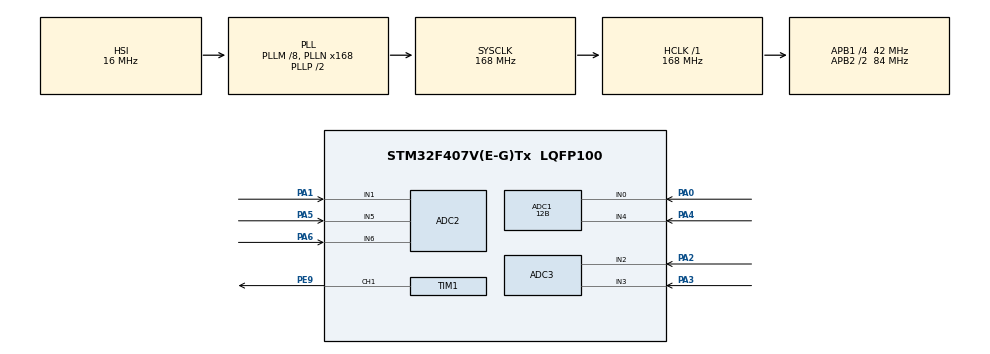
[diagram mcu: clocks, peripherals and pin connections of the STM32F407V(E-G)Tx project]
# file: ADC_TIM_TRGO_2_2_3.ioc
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ADC1.Channel-39\#ChannelRegularConversion=ADC_CHANNEL_0
ADC1.Channel-40\#ChannelInjectedConversion=ADC_CHANNEL_0
ADC1.Channel-41\#ChannelInjectedConversion=ADC_CHANNEL_4
ADC1.ClockPrescaler=ADC_CLOCK_SYNC_PCLK_DIV4
ADC1.ContinuousConvMode=DISABLE
ADC1.DMAContinuousRequests=DISABLE
ADC1.DataAlign=ADC_DATAALIGN_RIGHT
ADC1.DiscontinuousConvMode=DISABLE
ADC1.EOCSelection=ADC_EOC_SINGLE_CONV
ADC1.EnableAnalogWatchDog=false
ADC1.ExternalTrigConv=ADC_SOFTWARE_START
ADC1.ExternalTrigConvEdge=ADC_EXTERNALTRIGCONVEDGE_NONE
ADC1.ExternalTrigInjecConv=ADC_EXTERNALTRIGINJECCONV_T1_TRGO
ADC1.ExternalTrigInjecConvEdge=ADC_EXTERNALTRIGINJECCONVEDGE_RISING
ADC1.InjNumberOfConversion=2
ADC1.InjectedConvMode=None
ADC1.InjectedOffset-40\#ChannelInjectedConversion=0
ADC1.InjectedOffset-41\#ChannelInjectedConversion=0
ADC1.NbrOfConversion=1
ADC1.NbrOfConversionFlag=1
ADC1.Rank-39\#ChannelRegularConversion=1
ADC1.Rank-40\#ChannelInjectedConversion=1
ADC1.Rank-41\#ChannelInjectedConversion=2
ADC1.Resolution=ADC_RESOLUTION_12B
ADC1.SamplingTime-39\#ChannelRegularConversion=ADC_SAMPLETIME_3CYCLES
ADC1.SamplingTime-40\#ChannelInjectedConversion=ADC_SAMPLETIME_3CYCLES
ADC1.SamplingTime-41\#ChannelInjectedConversion=ADC_SAMPLETIME_3CYCLES
ADC1.ScanConvMode=ENABLE
ADC1.master=1
ADC2.Channel-0\#ChannelRegularConversion=ADC_CHANNEL_1
ADC2.Channel-1\#ChannelInjectedConversion=ADC_CHANNEL_1
ADC2.Channel-2\#ChannelInjectedConversion=ADC_CHANNEL_5
ADC2.Channel-3\#ChannelInjectedConversion=ADC_CHANNEL_6
ADC2.ContinuousConvMode=DISABLE
ADC2.ExternalTrigInjecConv=ADC_EXTERNALTRIGINJECCONV_T1_TRGO
ADC2.InjNumberOfConversion=3
ADC2.InjectedOffset-1\#ChannelInjectedConversion=0
ADC2.InjectedOffset-2\#ChannelInjectedConversion=0
ADC2.InjectedOffset-3\#ChannelInjectedConversion=0
ADC2.NbrOfConversionFlag=1
ADC2.Rank-0\#ChannelRegularConversion=1
ADC2.Rank-1\#ChannelInjectedConversion=1
ADC2.Rank-2\#ChannelInjectedConversion=2
ADC2.Rank-3\#ChannelInjectedConversion=3
ADC2.SamplingTime-0\#ChannelRegularConversion=ADC_SAMPLETIME_3CYCLES
ADC2.SamplingTime-1\#ChannelInjectedConversion=ADC_SAMPLETIME_3CYCLES
ADC2.SamplingTime-2\#ChannelInjectedConversion=ADC_SAMPLETIME_3CYCLES
ADC2.SamplingTime-3\#ChannelInjectedConversion=ADC_SAMPLETIME_3CYCLES
ADC2.ScanConvMode=ENABLE
ADC3.Channel-4\#ChannelRegularConversion=ADC_CHANNEL_2
ADC3.Channel-5\#ChannelInjectedConversion=ADC_CHANNEL_2
ADC3.Channel-6\#ChannelInjectedConversion=ADC_CHANNEL_3
ADC3.ContinuousConvMode=DISABLE
ADC3.ExternalTrigInjecConv=ADC_EXTERNALTRIGINJECCONV_T1_TRGO
ADC3.InjNumberOfConversion=2
ADC3.InjectedOffset-5\#ChannelInjectedConversion=0
ADC3.InjectedOffset-6\#ChannelInjectedConversion=0
ADC3.NbrOfConversionFlag=1
ADC3.Rank-4\#ChannelRegularConversion=1
ADC3.Rank-5\#ChannelInjectedConversion=1
ADC3.Rank-6\#ChannelInjectedConversion=2
ADC3.SamplingTime-4\#ChannelRegularConversion=ADC_SAMPLETIME_3CYCLES
ADC3.SamplingTime-5\#ChannelInjectedConversion=ADC_SAMPLETIME_3CYCLES
ADC3.SamplingTime-6\#ChannelInjectedConversion=ADC_SAMPLETIME_3CYCLES
ADC3.ScanConvMode=ENABLE
Mcu.Family=STM32F4
Mcu.Name=STM32F407V(E-G)Tx
Mcu.Package=LQFP100
NVIC.ADC_IRQn=true\:0\:0\:false\:false\:true
NVIC.PriorityGroup=NVIC_PRIORITYGROUP_4
PA0-WKUP.Signal=ADCx_IN0
PA1.Signal=ADCx_IN1
PA2.Signal=ADCx_IN2
PA3.Signal=ADCx_IN3
PA4.Signal=ADCx_IN4
PA5.Signal=ADCx_IN5
PA6.Signal=ADCx_IN6
PE9.Signal=S_TIM1_CH1
ProjectManager.HeapSize=0x200
ProjectManager.StackSize=0x400
ProjectManager.TargetToolchain=TrueSTUDIO
RCC.48MHZClocksFreq_Value=84000000
RCC.AHBFreq_Value=168000000
RCC.APB1CLKDivider=RCC_HCLK_DIV4
RCC.APB1Freq_Value=42000000
RCC.APB1TimFreq_Value=84000000
RCC.APB2CLKDivider=RCC_HCLK_DIV2
RCC.APB2Freq_Value=84000000
RCC.APB2TimFreq_Value=168000000
RCC.CortexFreq_Value=168000000
RCC.HCLKFreq_Value=168000000
RCC.HSE_VALUE=25000000
RCC.HSI_VALUE=16000000
RCC.LSE_VALUE=32768
RCC.PLLM=8
RCC.PLLN=168
RCC.SYSCLKFreq_VALUE=168000000
RCC.SYSCLKSource=RCC_SYSCLKSOURCE_PLLCLK
RCC.VCOOutputFreq_Value=336000000
SH.ADCx_IN0.0=ADC1_IN0,IN0
SH.ADCx_IN1.0=ADC2_IN1,IN1
SH.ADCx_IN2.0=ADC3_IN2,IN2
SH.ADCx_IN3.0=ADC3_IN3,IN3
SH.ADCx_IN4.0=ADC1_IN4,IN4
SH.ADCx_IN5.0=ADC2_IN5,IN5
SH.ADCx_IN6.0=ADC2_IN6,IN6
SH.S_TIM1_CH1.0=TIM1_CH1,PWM Generation1 CH1
TIM1.Channel-PWM\ Generation1\ CH1=TIM_CHANNEL_1
TIM1.Period=4096
TIM1.Prescaler=1
TIM1.Pulse-PWM\ Generation1\ CH1=0
TIM1.TIM_MasterOutputTrigger=TIM_TRGO_UPDATE
TIM1.TIM_MasterSlaveMode=TIM_MASTERSLAVEMODE_ENABLE
board=ADC_TIM_TRGO_2_2_3

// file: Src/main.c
/**
  ******************************************************************************
  * File Name          : main.c
  * Description        : Main program body
  ******************************************************************************
  ** This notice applies to any and all portions of this file
  * that are not between comment pairs USER CODE BEGIN and
  * USER CODE END. Other portions of this file, whether
  * inserted by the user or by software development tools
  * are owned by their respective copyright owners.
  *
  * COPYRIGHT(c) 2021 STMicroelectronics
  *
  * Redistribution and use in source and binary forms, with or without modification,
  * are permitted provided that the following conditions are met:
  *   1. Redistributions of source code must retain the above copyright notice,
  *      this list of conditions and the following disclaimer.
  *   2. Redistributions in binary form must reproduce the above copyright notice,
  *      this list of conditions and the following disclaimer in the documentation
  *      and/or other materials provided with the distribution.
  *   3. Neither the name of STMicroelectronics nor the names of its contributors
  *      may be used to endorse or promote products derived from this software
  *      without specific prior written permission.
  *
  * THIS SOFTWARE IS PROVIDED BY THE COPYRIGHT HOLDERS AND CONTRIBUTORS "AS IS"
  * AND ANY EXPRESS OR IMPLIED WARRANTIES, INCLUDING, BUT NOT LIMITED TO, THE
  * IMPLIED WARRANTIES OF MERCHANTABILITY AND FITNESS FOR A PARTICULAR PURPOSE ARE
  * DISCLAIMED. IN NO EVENT SHALL THE COPYRIGHT HOLDER OR CONTRIBUTORS BE LIABLE
  * FOR ANY DIRECT, INDIRECT, INCIDENTAL, SPECIAL, EXEMPLARY, OR CONSEQUENTIAL
  * DAMAGES (INCLUDING, BUT NOT LIMITED TO, PROCUREMENT OF SUBSTITUTE GOODS OR
  * SERVICES; LOSS OF USE, DATA, OR PROFITS; OR BUSINESS INTERRUPTION) HOWEVER
  * CAUSED AND ON ANY THEORY OF LIABILITY, WHETHER IN CONTRACT, STRICT LIABILITY,
  * OR TORT (INCLUDING NEGLIGENCE OR OTHERWISE) ARISING IN ANY WAY OUT OF THE USE
  * OF THIS SOFTWARE, EVEN IF ADVISED OF THE POSSIBILITY OF SUCH DAMAGE.
  *
  ******************************************************************************
  */
#include "main.h"
#include "stm32f4xx_hal.h"

ADC_HandleTypeDef hadc1;
ADC_HandleTypeDef hadc2;
ADC_HandleTypeDef hadc3;

TIM_HandleTypeDef htim1;

/* USER CODE BEGIN PV */
/* Private variables ---------------------------------------------------------*/

/* USER CODE END PV */

void SystemClock_Config(void);
static void MX_GPIO_Init(void);
static void MX_ADC3_Init(void);
static void MX_ADC2_Init(void);
static void MX_ADC1_Init(void);
static void MX_TIM1_Init(void);

void HAL_TIM_MspPostInit(TIM_HandleTypeDef *htim);

/* USER CODE BEGIN PFP */
/* Private function prototypes -----------------------------------------------*/

/* USER CODE END PFP */

int main(void)
{

  /* MCU Configuration----------------------------------------------------------*/

  /* Reset of all peripherals, Initializes the Flash interface and the Systick. */
  HAL_Init();

  /* Configure the system clock */
  SystemClock_Config();

  /* Initialize all configured peripherals */
  MX_GPIO_Init();
  MX_ADC3_Init();
  MX_ADC2_Init();
  MX_ADC1_Init();
  MX_TIM1_Init();

  /* USER CODE END 2 */
  /* USER CODE BEGIN 2 */
  /* USER CODE BEGIN 2 */
  HAL_ADCEx_InjectedStart_IT(&hadc1);
  HAL_ADCEx_InjectedStart_IT(&hadc2);
  HAL_ADCEx_InjectedStart_IT(&hadc3);
  /* USER CODE END 2 */

  /* Infinite loop */
  while (1)
  {

  }

}

__IO uint16_t value0 = 0;
__IO uint16_t value1 = 0;
__IO uint16_t value2 = 0;
__IO uint16_t value3 = 0;
__IO uint16_t value4 = 0;
__IO uint16_t value5 = 0;
__IO uint16_t value6 = 0;

void HAL_ADCEx_InjectedConvCpltCallback(ADC_HandleTypeDef* AdcHandle)
{
  /* Get the converted value of injected channel */
  if (AdcHandle == &hadc1)
  {
  	  value0 = HAL_ADCEx_InjectedGetValue(AdcHandle, ADC_INJECTED_RANK_1);
  	  value1 = HAL_ADCEx_InjectedGetValue(AdcHandle, ADC_INJECTED_RANK_2);

  }

  if (AdcHandle == &hadc2)
  {
  	  value2 = HAL_ADCEx_InjectedGetValue(AdcHandle, ADC_INJECTED_RANK_1);
  	  value3 = HAL_ADCEx_InjectedGetValue(AdcHandle, ADC_INJECTED_RANK_2);
  	  value4 = HAL_ADCEx_InjectedGetValue(AdcHandle, ADC_INJECTED_RANK_3);
  }

  if (AdcHandle == &hadc3)
  {

  	  value5 = HAL_ADCEx_InjectedGetValue(AdcHandle, ADC_INJECTED_RANK_1);
  	  value6 = HAL_ADCEx_InjectedGetValue(AdcHandle, ADC_INJECTED_RANK_2);
  }

}

/** System Clock Configuration
*/
void SystemClock_Config(void)
{

  RCC_OscInitTypeDef RCC_OscInitStruct;
  RCC_ClkInitTypeDef RCC_ClkInitStruct;

    /**Configure the main internal regulator output voltage
    */
  __HAL_RCC_PWR_CLK_ENABLE();

  __HAL_PWR_VOLTAGESCALING_CONFIG(PWR_REGULATOR_VOLTAGE_SCALE1);

    /**Initializes the CPU, AHB and APB busses clocks
    */
  RCC_OscInitStruct.OscillatorType = RCC_OSCILLATORTYPE_HSI;
  RCC_OscInitStruct.HSIState = RCC_HSI_ON;
  RCC_OscInitStruct.HSICalibrationValue = 16;
  RCC_OscInitStruct.PLL.PLLState = RCC_PLL_ON;
  RCC_OscInitStruct.PLL.PLLSource = RCC_PLLSOURCE_HSI;
  RCC_OscInitStruct.PLL.PLLM = 8;
  RCC_OscInitStruct.PLL.PLLN = 168;
  RCC_OscInitStruct.PLL.PLLP = RCC_PLLP_DIV2;
  RCC_OscInitStruct.PLL.PLLQ = 4;
  if (HAL_RCC_OscConfig(&RCC_OscInitStruct) != HAL_OK)
  {
    _Error_Handler(__FILE__, __LINE__);
  }

    /**Initializes the CPU, AHB and APB busses clocks
    */
  RCC_ClkInitStruct.ClockType = RCC_CLOCKTYPE_HCLK|RCC_CLOCKTYPE_SYSCLK
                              |RCC_CLOCKTYPE_PCLK1|RCC_CLOCKTYPE_PCLK2;
  RCC_ClkInitStruct.SYSCLKSource = RCC_SYSCLKSOURCE_PLLCLK;
  RCC_ClkInitStruct.AHBCLKDivider = RCC_SYSCLK_DIV1;
  RCC_ClkInitStruct.APB1CLKDivider = RCC_HCLK_DIV4;
  RCC_ClkInitStruct.APB2CLKDivider = RCC_HCLK_DIV2;

  if (HAL_RCC_ClockConfig(&RCC_ClkInitStruct, FLASH_LATENCY_5) != HAL_OK)
  {
    _Error_Handler(__FILE__, __LINE__);
  }

    /**Configure the Systick interrupt time
    */
  HAL_SYSTICK_Config(HAL_RCC_GetHCLKFreq()/1000);

    /**Configure the Systick
    */
  HAL_SYSTICK_CLKSourceConfig(SYSTICK_CLKSOURCE_HCLK);

  /* SysTick_IRQn interrupt configuration */
  HAL_NVIC_SetPriority(SysTick_IRQn, 0, 0);
}

/* ADC1 init function */
static void MX_ADC1_Init(void)
{

  ADC_ChannelConfTypeDef sConfig;
  ADC_InjectionConfTypeDef sConfigInjected;

    /**Configure the global features of the ADC (Clock, Resolution, Data Alignment and number of conversion)
    */
  hadc1.Instance = ADC1;
  hadc1.Init.ClockPrescaler = ADC_CLOCK_SYNC_PCLK_DIV4;
  hadc1.Init.Resolution = ADC_RESOLUTION_12B;
  hadc1.Init.ScanConvMode = ENABLE;
  hadc1.Init.ContinuousConvMode = DISABLE;
  hadc1.Init.DiscontinuousConvMode = DISABLE;
  hadc1.Init.ExternalTrigConvEdge = ADC_EXTERNALTRIGCONVEDGE_NONE;
  hadc1.Init.ExternalTrigConv = ADC_SOFTWARE_START;
  hadc1.Init.DataAlign = ADC_DATAALIGN_RIGHT;
  hadc1.Init.NbrOfConversion = 1;
  hadc1.Init.DMAContinuousRequests = DISABLE;
  hadc1.Init.EOCSelection = ADC_EOC_SINGLE_CONV;
  if (HAL_ADC_Init(&hadc1) != HAL_OK)
  {
    _Error_Handler(__FILE__, __LINE__);
  }

    /**Configure for the selected ADC regular channel its corresponding rank in the sequencer and its sample time.
    */
  sConfig.Channel = ADC_CHANNEL_0;
  sConfig.Rank = 1;
  sConfig.SamplingTime = ADC_SAMPLETIME_3CYCLES;
  if (HAL_ADC_ConfigChannel(&hadc1, &sConfig) != HAL_OK)
  {
    _Error_Handler(__FILE__, __LINE__);
  }

    /**Configures for the selected ADC injected channel its corresponding rank in the sequencer and its sample time
    */
  sConfigInjected.InjectedChannel = ADC_CHANNEL_0;
  sConfigInjected.InjectedRank = 1;
  sConfigInjected.InjectedNbrOfConversion = 2;
  sConfigInjected.InjectedSamplingTime = ADC_SAMPLETIME_3CYCLES;
  sConfigInjected.ExternalTrigInjecConvEdge = ADC_EXTERNALTRIGINJECCONVEDGE_RISING;
  sConfigInjected.ExternalTrigInjecConv = ADC_EXTERNALTRIGINJECCONV_T1_TRGO;
  sConfigInjected.AutoInjectedConv = DISABLE;
  sConfigInjected.InjectedDiscontinuousConvMode = DISABLE;
  sConfigInjected.InjectedOffset = 0;
  if (HAL_ADCEx_InjectedConfigChannel(&hadc1, &sConfigInjected) != HAL_OK)
  {
    _Error_Handler(__FILE__, __LINE__);
  }

    /**Configures for the selected ADC injected channel its corresponding rank in the sequencer and its sample time
    */
  sConfigInjected.InjectedChannel = ADC_CHANNEL_4;
  sConfigInjected.InjectedRank = 2;
  if (HAL_ADCEx_InjectedConfigChannel(&hadc1, &sConfigInjected) != HAL_OK)
  {
    _Error_Handler(__FILE__, __LINE__);
  }

}

/* ADC2 init function */
static void MX_ADC2_Init(void)
{

  ADC_ChannelConfTypeDef sConfig;
  ADC_InjectionConfTypeDef sConfigInjected;

    /**Configure the global features of the ADC (Clock, Resolution, Data Alignment and number of conversion)
    */
  hadc2.Instance = ADC2;
  hadc2.Init.ClockPrescaler = ADC_CLOCK_SYNC_PCLK_DIV4;
  hadc2.Init.Resolution = ADC_RESOLUTION_12B;
  hadc2.Init.ScanConvMode = ENABLE;
  hadc2.Init.ContinuousConvMode = DISABLE;
  hadc2.Init.DiscontinuousConvMode = DISABLE;
  hadc2.Init.ExternalTrigConvEdge = ADC_EXTERNALTRIGCONVEDGE_NONE;
  hadc2.Init.ExternalTrigConv = ADC_SOFTWARE_START;
  hadc2.Init.DataAlign = ADC_DATAALIGN_RIGHT;
  hadc2.Init.NbrOfConversion = 1;
  hadc2.Init.DMAContinuousRequests = DISABLE;
  hadc2.Init.EOCSelection = ADC_EOC_SINGLE_CONV;
  if (HAL_ADC_Init(&hadc2) != HAL_OK)
  {
    _Error_Handler(__FILE__, __LINE__);
  }

    /**Configure for the selected ADC regular channel its corresponding rank in the sequencer and its sample time.
    */
  sConfig.Channel = ADC_CHANNEL_1;
  sConfig.Rank = 1;
  sConfig.SamplingTime = ADC_SAMPLETIME_3CYCLES;
  if (HAL_ADC_ConfigChannel(&hadc2, &sConfig) != HAL_OK)
  {
    _Error_Handler(__FILE__, __LINE__);
  }

    /**Configures for the selected ADC injected channel its corresponding rank in the sequencer and its sample time
    */
  sConfigInjected.InjectedChannel = ADC_CHANNEL_1;
  sConfigInjected.InjectedRank = 1;
  sConfigInjected.InjectedNbrOfConversion = 3;
  sConfigInjected.InjectedSamplingTime = ADC_SAMPLETIME_3CYCLES;
  sConfigInjected.ExternalTrigInjecConvEdge = ADC_EXTERNALTRIGINJECCONVEDGE_RISING;
  sConfigInjected.ExternalTrigInjecConv = ADC_EXTERNALTRIGINJECCONV_T1_TRGO;
  sConfigInjected.AutoInjectedConv = DISABLE;
  sConfigInjected.InjectedDiscontinuousConvMode = DISABLE;
  sConfigInjected.InjectedOffset = 0;
  if (HAL_ADCEx_InjectedConfigChannel(&hadc2, &sConfigInjected) != HAL_OK)
  {
    _Error_Handler(__FILE__, __LINE__);
  }

    /**Configures for the selected ADC injected channel its corresponding rank in the sequencer and its sample time
    */
  sConfigInjected.InjectedChannel = ADC_CHANNEL_5;
  sConfigInjected.InjectedRank = 2;
  if (HAL_ADCEx_InjectedConfigChannel(&hadc2, &sConfigInjected) != HAL_OK)
  {
    _Error_Handler(__FILE__, __LINE__);
  }

    /**Configures for the selected ADC injected channel its corresponding rank in the sequencer and its sample time
    */
  sConfigInjected.InjectedChannel = ADC_CHANNEL_6;
  sConfigInjected.InjectedRank = 3;
  if (HAL_ADCEx_InjectedConfigChannel(&hadc2, &sConfigInjected) != HAL_OK)
  {
    _Error_Handler(__FILE__, __LINE__);
  }

}

/* ADC3 init function */
static void MX_ADC3_Init(void)
{

  ADC_ChannelConfTypeDef sConfig;
  ADC_InjectionConfTypeDef sConfigInjected;

    /**Configure the global features of the ADC (Clock, Resolution, Data Alignment and number of conversion)
    */
  hadc3.Instance = ADC3;
  hadc3.Init.ClockPrescaler = ADC_CLOCK_SYNC_PCLK_DIV4;
  hadc3.Init.Resolution = ADC_RESOLUTION_12B;
  hadc3.Init.ScanConvMode = ENABLE;
  hadc3.Init.ContinuousConvMode = DISABLE;
  hadc3.Init.DiscontinuousConvMode = DISABLE;
  hadc3.Init.ExternalTrigConvEdge = ADC_EXTERNALTRIGCONVEDGE_NONE;
  hadc3.Init.ExternalTrigConv = ADC_SOFTWARE_START;
  hadc3.Init.DataAlign = ADC_DATAALIGN_RIGHT;
  hadc3.Init.NbrOfConversion = 1;
  hadc3.Init.DMAContinuousRequests = DISABLE;
  hadc3.Init.EOCSelection = ADC_EOC_SINGLE_CONV;
  if (HAL_ADC_Init(&hadc3) != HAL_OK)
  {
    _Error_Handler(__FILE__, __LINE__);
  }

    /**Configure for the selected ADC regular channel its corresponding rank in the sequencer and its sample time.
    */
  sConfig.Channel = ADC_CHANNEL_2;
  sConfig.Rank = 1;
  sConfig.SamplingTime = ADC_SAMPLETIME_3CYCLES;
  if (HAL_ADC_ConfigChannel(&hadc3, &sConfig) != HAL_OK)
  {
    _Error_Handler(__FILE__, __LINE__);
  }

    /**Configures for the selected ADC injected channel its corresponding rank in the sequencer and its sample time
    */
  sConfigInjected.InjectedChannel = ADC_CHANNEL_2;
  sConfigInjected.InjectedRank = 1;
  sConfigInjected.InjectedNbrOfConversion = 2;
  sConfigInjected.InjectedSamplingTime = ADC_SAMPLETIME_3CYCLES;
  sConfigInjected.ExternalTrigInjecConvEdge = ADC_EXTERNALTRIGINJECCONVEDGE_RISING;
  sConfigInjected.ExternalTrigInjecConv = ADC_EXTERNALTRIGINJECCONV_T1_TRGO;
  sConfigInjected.AutoInjectedConv = DISABLE;
  sConfigInjected.InjectedDiscontinuousConvMode = DISABLE;
  sConfigInjected.InjectedOffset = 0;
  if (HAL_ADCEx_InjectedConfigChannel(&hadc3, &sConfigInjected) != HAL_OK)
  {
    _Error_Handler(__FILE__, __LINE__);
  }

    /**Configures for the selected ADC injected channel its corresponding rank in the sequencer and its sample time
    */
  sConfigInjected.InjectedChannel = ADC_CHANNEL_3;
  sConfigInjected.InjectedRank = 2;
  if (HAL_ADCEx_InjectedConfigChannel(&hadc3, &sConfigInjected) != HAL_OK)
  {
    _Error_Handler(__FILE__, __LINE__);
  }

}

/* TIM1 init function */
static void MX_TIM1_Init(void)
{

  TIM_MasterConfigTypeDef sMasterConfig;
  TIM_OC_InitTypeDef sConfigOC;
  TIM_BreakDeadTimeConfigTypeDef sBreakDeadTimeConfig;

  htim1.Instance = TIM1;
  htim1.Init.Prescaler = 1;
  htim1.Init.CounterMode = TIM_COUNTERMODE_UP;
  htim1.Init.Period = 4096;
  htim1.Init.ClockDivision = TIM_CLOCKDIVISION_DIV1;
  htim1.Init.RepetitionCounter = 0;
  if (HAL_TIM_PWM_Init(&htim1) != HAL_OK)
  {
    _Error_Handler(__FILE__, __LINE__);
  }

  sMasterConfig.MasterOutputTrigger = TIM_TRGO_UPDATE;
  sMasterConfig.MasterSlaveMode = TIM_MASTERSLAVEMODE_ENABLE;
  if (HAL_TIMEx_MasterConfigSynchronization(&htim1, &sMasterConfig) != HAL_OK)
  {
    _Error_Handler(__FILE__, __LINE__);
  }

  sConfigOC.OCMode = TIM_OCMODE_PWM1;
  sConfigOC.Pulse = 0;
  sConfigOC.OCPolarity = TIM_OCPOLARITY_HIGH;
  sConfigOC.OCNPolarity = TIM_OCNPOLARITY_HIGH;
  sConfigOC.OCFastMode = TIM_OCFAST_DISABLE;
  sConfigOC.OCIdleState = TIM_OCIDLESTATE_RESET;
  sConfigOC.OCNIdleState = TIM_OCNIDLESTATE_RESET;
  if (HAL_TIM_PWM_ConfigChannel(&htim1, &sConfigOC, TIM_CHANNEL_1) != HAL_OK)
  {
    _Error_Handler(__FILE__, __LINE__);
  }

  sBreakDeadTimeConfig.OffStateRunMode = TIM_OSSR_DISABLE;
  sBreakDeadTimeConfig.OffStateIDLEMode = TIM_OSSI_DISABLE;
  sBreakDeadTimeConfig.LockLevel = TIM_LOCKLEVEL_OFF;
  sBreakDeadTimeConfig.DeadTime = 0;
  sBreakDeadTimeConfig.BreakState = TIM_BREAK_DISABLE;
  sBreakDeadTimeConfig.BreakPolarity = TIM_BREAKPOLARITY_HIGH;
  sBreakDeadTimeConfig.AutomaticOutput = TIM_AUTOMATICOUTPUT_DISABLE;
  if (HAL_TIMEx_ConfigBreakDeadTime(&htim1, &sBreakDeadTimeConfig) != HAL_OK)
  {
    _Error_Handler(__FILE__, __LINE__);
  }

  HAL_TIM_MspPostInit(&htim1);
  HAL_TIM_PWM_Start_IT(&htim1, TIM_CHANNEL_1);

  __HAL_TIM_ENABLE_IT(&htim1, TIM_IT_UPDATE);

}

/** Pinout Configuration
*/
static void MX_GPIO_Init(void)
{

  /* GPIO Ports Clock Enable */
  __HAL_RCC_GPIOA_CLK_ENABLE();
  __HAL_RCC_GPIOE_CLK_ENABLE();

}

void _Error_Handler(char * file, int line)
{
  while(1)
  {
  }
}

/************************ (C) COPYRIGHT STMicroelectronics *****END OF FILE****/
